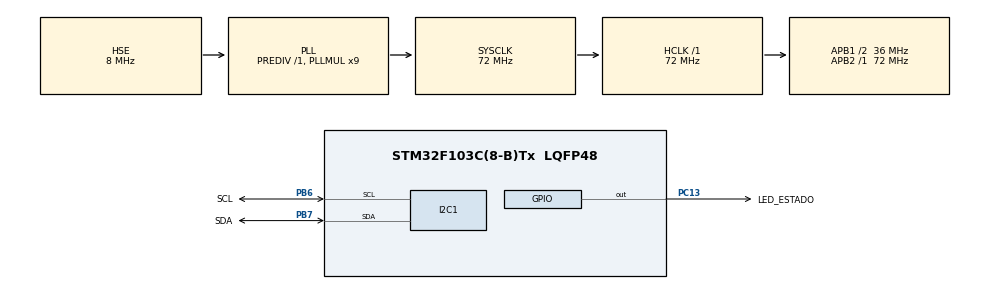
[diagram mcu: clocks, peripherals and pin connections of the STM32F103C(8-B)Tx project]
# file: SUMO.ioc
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Mcu.Family=STM32F1
Mcu.Name=STM32F103C(8-B)Tx
Mcu.Package=LQFP48
NVIC.PriorityGroup=NVIC_PRIORITYGROUP_4
NVIC.TIM2_IRQn=true\:0\:0\:false\:false\:true\:true\:true\:true
PA13.Mode=Serial_Wire
PA13.Signal=SYS_JTMS-SWDIO
PA14.Mode=Serial_Wire
PA14.Signal=SYS_JTCK-SWCLK
PB6.GPIO_Label=SCL
PB6.Mode=I2C
PB6.Signal=I2C1_SCL
PB7.GPIO_Label=SDA
PB7.Mode=I2C
PB7.Signal=I2C1_SDA
PC13-TAMPER-RTC.GPIO_Label=LED_ESTADO
PC13-TAMPER-RTC.Signal=GPIO_Output
PD0-OSC_IN.Mode=HSE-External-Oscillator
PD0-OSC_IN.Signal=RCC_OSC_IN
PD1-OSC_OUT.Mode=HSE-External-Oscillator
PD1-OSC_OUT.Signal=RCC_OSC_OUT
ProjectManager.HeapSize=0x200
ProjectManager.StackSize=0x400
ProjectManager.TargetToolchain=STM32CubeIDE
RCC.ADCPresc=RCC_ADCPCLK2_DIV6
RCC.AHBFreq_Value=72000000
RCC.APB1CLKDivider=RCC_HCLK_DIV2
RCC.APB1Freq_Value=36000000
RCC.APB1TimFreq_Value=72000000
RCC.APB2Freq_Value=72000000
RCC.APB2TimFreq_Value=72000000
RCC.HCLKFreq_Value=72000000
RCC.PLLMUL=RCC_PLL_MUL9
RCC.PLLSourceVirtual=RCC_PLLSOURCE_HSE
RCC.SYSCLKFreq_VALUE=72000000
RCC.SYSCLKSource=RCC_SYSCLKSOURCE_PLLCLK
RCC.USBFreq_Value=72000000
TIM2.Period=999
TIM2.Prescaler=71
VP_TIM2_VS_ClockSourceINT.Mode=Internal
board=custom

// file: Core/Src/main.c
/* USER CODE BEGIN Header */
/**
  ******************************************************************************
  * @file           : main.c
  * @brief          : Robot sumo con pantalla OLED - Expresiones faciales
  ******************************************************************************
  */
/* USER CODE END Header */

#include "main.h"
#include "ssd1306.h"
#include "faces.h"

/* USER CODE BEGIN PTD */
typedef enum {
    ESTADO_NEUTRO,
    ESTADO_LUCHA,
    ESTADO_DOLOR,
    ESTADO_CONCENTRACION,
    ESTADO_FELIZ,
    ESTADO_TRISTE
} estado_robot_t;
/* USER CODE END PTD */

I2C_HandleTypeDef hi2c1;
TIM_HandleTypeDef htim2;

void SystemClock_Config(void);
static void MX_GPIO_Init(void);
static void MX_TIM2_Init(void);
static void MX_I2C1_Init(void);
void mostrar_cara(estado_robot_t estado);

/* USER CODE BEGIN 0 */
void mostrar_cara(estado_robot_t estado)
{
    switch(estado)
    {
        case ESTADO_NEUTRO:
            ssd1306_LoadFullBitmap(cara_neutra);
            break;
        case ESTADO_LUCHA:
            ssd1306_LoadFullBitmap(cara_sorpresa);   // Usamos sorpresa como lucha
            break;
        case ESTADO_DOLOR:
            ssd1306_LoadFullBitmap(cara_dolor);
            break;
        case ESTADO_CONCENTRACION:
            ssd1306_LoadFullBitmap(cara_concentracion);
            break;
        case ESTADO_FELIZ:
            ssd1306_LoadFullBitmap(cara_feliz);
            break;
        case ESTADO_TRISTE:
            ssd1306_LoadFullBitmap(cara_triste);
            break;
        default:
            ssd1306_LoadFullBitmap(cara_neutra);
            break;
    }
}
/* USER CODE END 0 */

int main(void)
{

  HAL_Init();

  SystemClock_Config();

  MX_GPIO_Init();
  MX_TIM2_Init();
  MX_I2C1_Init();

  /* USER CODE BEGIN 2 */
  ssd1306_Init();
  mostrar_cara(ESTADO_NEUTRO);
  /* USER CODE END 2 */

  /* Infinite loop */
  /* USER CODE BEGIN WHILE */
  uint32_t tiempo_anterior = HAL_GetTick();
  uint8_t paso = 0;

  while (1)
  {
    // Demo: cambia de expresión cada 3 segundos
    if ((HAL_GetTick() - tiempo_anterior) > 3000)
    {
        tiempo_anterior = HAL_GetTick();
        paso = (paso + 1) % 6;
        mostrar_cara((estado_robot_t)paso);
    }
    HAL_Delay(10);
  }
  /* USER CODE END 3 */
}

void SystemClock_Config(void)
{
  RCC_OscInitTypeDef RCC_OscInitStruct = {0};
  RCC_ClkInitTypeDef RCC_ClkInitStruct = {0};

  RCC_OscInitStruct.OscillatorType = RCC_OSCILLATORTYPE_HSE;
  RCC_OscInitStruct.HSEState = RCC_HSE_ON;
  RCC_OscInitStruct.HSEPredivValue = RCC_HSE_PREDIV_DIV1;
  RCC_OscInitStruct.HSIState = RCC_HSI_ON;
  RCC_OscInitStruct.PLL.PLLState = RCC_PLL_ON;
  RCC_OscInitStruct.PLL.PLLSource = RCC_PLLSOURCE_HSE;
  RCC_OscInitStruct.PLL.PLLMUL = RCC_PLL_MUL9;
  if (HAL_RCC_OscConfig(&RCC_OscInitStruct) != HAL_OK)
  {
    Error_Handler();
  }

  RCC_ClkInitStruct.ClockType = RCC_CLOCKTYPE_HCLK|RCC_CLOCKTYPE_SYSCLK
                              |RCC_CLOCKTYPE_PCLK1|RCC_CLOCKTYPE_PCLK2;
  RCC_ClkInitStruct.SYSCLKSource = RCC_SYSCLKSOURCE_PLLCLK;
  RCC_ClkInitStruct.AHBCLKDivider = RCC_SYSCLK_DIV1;
  RCC_ClkInitStruct.APB1CLKDivider = RCC_HCLK_DIV2;
  RCC_ClkInitStruct.APB2CLKDivider = RCC_HCLK_DIV1;

  if (HAL_RCC_ClockConfig(&RCC_ClkInitStruct, FLASH_LATENCY_2) != HAL_OK)
  {
    Error_Handler();
  }
}

static void MX_I2C1_Init(void)
{
  hi2c1.Instance = I2C1;
  hi2c1.Init.ClockSpeed = 100000;
  hi2c1.Init.DutyCycle = I2C_DUTYCYCLE_2;
  hi2c1.Init.OwnAddress1 = 0;
  hi2c1.Init.AddressingMode = I2C_ADDRESSINGMODE_7BIT;
  hi2c1.Init.DualAddressMode = I2C_DUALADDRESS_DISABLE;
  hi2c1.Init.OwnAddress2 = 0;
  hi2c1.Init.GeneralCallMode = I2C_GENERALCALL_DISABLE;
  hi2c1.Init.NoStretchMode = I2C_NOSTRETCH_DISABLE;
  if (HAL_I2C_Init(&hi2c1) != HAL_OK)
  {
    Error_Handler();
  }
}

static void MX_TIM2_Init(void)
{
  TIM_ClockConfigTypeDef sClockSourceConfig = {0};
  TIM_MasterConfigTypeDef sMasterConfig = {0};

  htim2.Instance = TIM2;
  htim2.Init.Prescaler = 71;
  htim2.Init.CounterMode = TIM_COUNTERMODE_UP;
  htim2.Init.Period = 999;
  htim2.Init.ClockDivision = TIM_CLOCKDIVISION_DIV1;
  htim2.Init.AutoReloadPreload = TIM_AUTORELOAD_PRELOAD_DISABLE;
  if (HAL_TIM_Base_Init(&htim2) != HAL_OK)
  {
    Error_Handler();
  }

  sClockSourceConfig.ClockSource = TIM_CLOCKSOURCE_INTERNAL;
  if (HAL_TIM_ConfigClockSource(&htim2, &sClockSourceConfig) != HAL_OK)
  {
    Error_Handler();
  }

  sMasterConfig.MasterOutputTrigger = TIM_TRGO_RESET;
  sMasterConfig.MasterSlaveMode = TIM_MASTERSLAVEMODE_DISABLE;
  if (HAL_TIMEx_MasterConfigSynchronization(&htim2, &sMasterConfig) != HAL_OK)
  {
    Error_Handler();
  }
}

static void MX_GPIO_Init(void)
{
  GPIO_InitTypeDef GPIO_InitStruct = {0};

  __HAL_RCC_GPIOC_CLK_ENABLE();
  __HAL_RCC_GPIOD_CLK_ENABLE();
  __HAL_RCC_GPIOA_CLK_ENABLE();
  __HAL_RCC_GPIOB_CLK_ENABLE();

  HAL_GPIO_WritePin(LED_ESTADO_GPIO_Port, LED_ESTADO_Pin, GPIO_PIN_RESET);

  GPIO_InitStruct.Pin = LED_ESTADO_Pin;
  GPIO_InitStruct.Mode = GPIO_MODE_OUTPUT_PP;
  GPIO_InitStruct.Pull = GPIO_NOPULL;
  GPIO_InitStruct.Speed = GPIO_SPEED_FREQ_LOW;
  HAL_GPIO_Init(LED_ESTADO_GPIO_Port, &GPIO_InitStruct);
}

/**
  * @brief Error handler
  */
void Error_Handler(void)
{
  __disable_irq();
  while (1)
  {
  }
}
